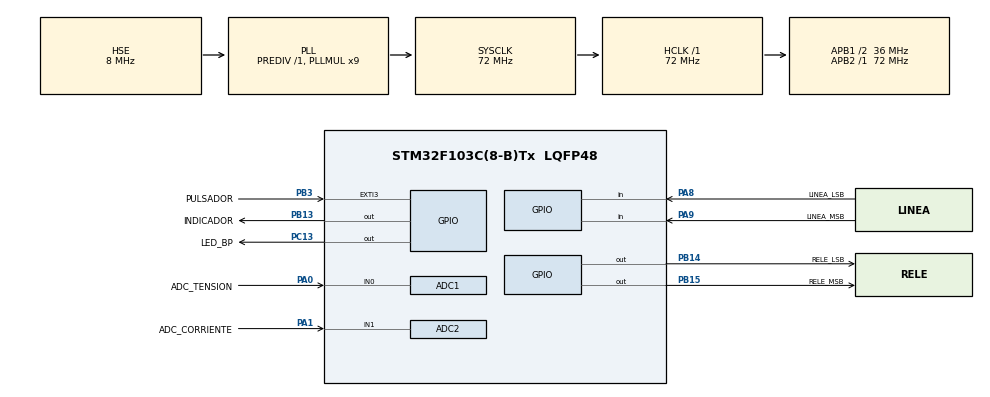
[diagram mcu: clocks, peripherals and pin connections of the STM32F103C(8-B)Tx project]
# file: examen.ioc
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ADC1.Channel-0\#ChannelRegularConversion=ADC_CHANNEL_0
ADC1.NbrOfConversionFlag=1
ADC1.Rank-0\#ChannelRegularConversion=1
ADC1.SamplingTime-0\#ChannelRegularConversion=ADC_SAMPLETIME_1CYCLE_5
ADC1.master=1
ADC2.Channel-0\#ChannelRegularConversion=ADC_CHANNEL_1
ADC2.NbrOfConversionFlag=1
ADC2.Rank-0\#ChannelRegularConversion=1
ADC2.SamplingTime-0\#ChannelRegularConversion=ADC_SAMPLETIME_1CYCLE_5
Dma.ADC1.0.Direction=DMA_PERIPH_TO_MEMORY
Dma.ADC1.0.Instance=DMA1_Channel1
Dma.ADC1.0.MemDataAlignment=DMA_MDATAALIGN_HALFWORD
Dma.ADC1.0.MemInc=DMA_MINC_ENABLE
Dma.ADC1.0.Mode=DMA_CIRCULAR
Dma.ADC1.0.PeriphDataAlignment=DMA_PDATAALIGN_HALFWORD
Dma.ADC1.0.PeriphInc=DMA_PINC_DISABLE
Dma.ADC1.0.Priority=DMA_PRIORITY_LOW
Dma.Request0=ADC1
Mcu.Family=STM32F1
Mcu.Name=STM32F103C(8-B)Tx
Mcu.Package=LQFP48
NVIC.DMA1_Channel1_IRQn=true\:0\:0\:false\:false\:true\:false\:true\:true
NVIC.PriorityGroup=NVIC_PRIORITYGROUP_4
PA0-WKUP.GPIO_Label=ADC_TENSION
PA0-WKUP.Signal=ADCx_IN0
PA1.GPIO_Label=ADC_CORRIENTE
PA1.Signal=ADCx_IN1
PA13.Mode=Serial_Wire
PA13.Signal=SYS_JTMS-SWDIO
PA14.Mode=Serial_Wire
PA14.Signal=SYS_JTCK-SWCLK
PA8.GPIO_Label=LINEA_LSB
PA8.Signal=GPIO_Input
PA9.GPIO_Label=LINEA_MSB
PA9.Signal=GPIO_Input
PB13.GPIO_Label=INDICADOR
PB13.Signal=GPIO_Output
PB14.GPIO_Label=RELE_LSB
PB14.Signal=GPIO_Output
PB15.GPIO_Label=RELE_MSB
PB15.Signal=GPIO_Output
PB3.GPIO_Label=PULSADOR
PB3.Signal=GPXTI3
PC13-TAMPER-RTC.GPIO_Label=LED_BP
PC13-TAMPER-RTC.Signal=GPIO_Output
PC14-OSC32_IN.Mode=LSE-External-Oscillator
PC14-OSC32_IN.Signal=RCC_OSC32_IN
PC15-OSC32_OUT.Mode=LSE-External-Oscillator
PC15-OSC32_OUT.Signal=RCC_OSC32_OUT
PD0-OSC_IN.Mode=HSE-External-Oscillator
PD0-OSC_IN.Signal=RCC_OSC_IN
PD1-OSC_OUT.Mode=HSE-External-Oscillator
PD1-OSC_OUT.Signal=RCC_OSC_OUT
ProjectManager.HeapSize=0x200
ProjectManager.StackSize=0x400
ProjectManager.TargetToolchain=STM32CubeIDE
RCC.AHBFreq_Value=72000000
RCC.APB1CLKDivider=RCC_HCLK_DIV2
RCC.APB1Freq_Value=36000000
RCC.APB1TimFreq_Value=72000000
RCC.APB2Freq_Value=72000000
RCC.APB2TimFreq_Value=72000000
RCC.HCLKFreq_Value=72000000
RCC.PLLMUL=RCC_PLL_MUL9
RCC.PLLSourceVirtual=RCC_PLLSOURCE_HSE
RCC.SYSCLKFreq_VALUE=72000000
RCC.SYSCLKSource=RCC_SYSCLKSOURCE_PLLCLK
RCC.USBFreq_Value=72000000
SH.ADCx_IN0.0=ADC1_IN0,IN0
SH.ADCx_IN1.0=ADC2_IN1,IN1
SH.ADCx_IN1.1=ADC1_IN1,IN1
board=custom

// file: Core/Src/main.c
/* USER CODE BEGIN Header */
/**
  ******************************************************************************
  * @file           : main.c
  * @brief          : Main program body
  ******************************************************************************
  * @attention
  *
  * <h2><center>&copy; Copyright (c) 2021 STMicroelectronics.
  * All rights reserved.</center></h2>
  *
  * This software component is licensed by ST under BSD 3-Clause license,
  * the "License"; You may not use this file except in compliance with the
  * License. You may obtain a copy of the License at:
  *                        opensource.org/licenses/BSD-3-Clause
  *
  ******************************************************************************
  */
/* USER CODE END Header */
#include "main.h"
#include "fsm.h"
#include "user_gpio.h"

ADC_HandleTypeDef hadc1;
ADC_HandleTypeDef hadc2;
DMA_HandleTypeDef hdma_adc1;

void SystemClock_Config(void);
static void MX_GPIO_Init(void);
static void MX_DMA_Init(void);
static void MX_ADC1_Init(void);
static void MX_ADC2_Init(void);

/* USER CODE BEGIN 0 */
void HAL_IncTick(void){
	uwTick += uwTickFreq;
	fsm_tick();
}
/* USER CODE END 0 */

int main(void)
{

  /* MCU Configuration--------------------------------------------------------*/

  /* Reset of all peripherals, Initializes the Flash interface and the Systick. */
  HAL_Init();

  /* Configure the system clock */
  SystemClock_Config();

  /* Initialize all configured peripherals */
  MX_GPIO_Init();
  MX_DMA_Init();
  MX_ADC1_Init();
  MX_ADC2_Init();
  /* USER CODE BEGIN 2 */
  fsm_init();
  user_gpio_init();
  /* USER CODE END 2 */

  /* Infinite loop */
  /* USER CODE BEGIN WHILE */
  while (1)
  {

	 fsm_runCycle();
	 user_gpio_loop();
    /* USER CODE END WHILE */

  }
}

void SystemClock_Config(void)
{
  RCC_OscInitTypeDef RCC_OscInitStruct = {0};
  RCC_ClkInitTypeDef RCC_ClkInitStruct = {0};
  RCC_PeriphCLKInitTypeDef PeriphClkInit = {0};

  /** Initializes the RCC Oscillators according to the specified parameters
  * in the RCC_OscInitTypeDef structure.
  */
  RCC_OscInitStruct.OscillatorType = RCC_OSCILLATORTYPE_HSE;
  RCC_OscInitStruct.HSEState = RCC_HSE_ON;
  RCC_OscInitStruct.HSEPredivValue = RCC_HSE_PREDIV_DIV1;
  RCC_OscInitStruct.HSIState = RCC_HSI_ON;
  RCC_OscInitStruct.PLL.PLLState = RCC_PLL_ON;
  RCC_OscInitStruct.PLL.PLLSource = RCC_PLLSOURCE_HSE;
  RCC_OscInitStruct.PLL.PLLMUL = RCC_PLL_MUL9;
  if (HAL_RCC_OscConfig(&RCC_OscInitStruct) != HAL_OK)
  {
    Error_Handler();
  }

  /** Initializes the CPU, AHB and APB buses clocks
  */
  RCC_ClkInitStruct.ClockType = RCC_CLOCKTYPE_HCLK|RCC_CLOCKTYPE_SYSCLK
                              |RCC_CLOCKTYPE_PCLK1|RCC_CLOCKTYPE_PCLK2;
  RCC_ClkInitStruct.SYSCLKSource = RCC_SYSCLKSOURCE_PLLCLK;
  RCC_ClkInitStruct.AHBCLKDivider = RCC_SYSCLK_DIV1;
  RCC_ClkInitStruct.APB1CLKDivider = RCC_HCLK_DIV2;
  RCC_ClkInitStruct.APB2CLKDivider = RCC_HCLK_DIV1;

  if (HAL_RCC_ClockConfig(&RCC_ClkInitStruct, FLASH_LATENCY_2) != HAL_OK)
  {
    Error_Handler();
  }
  PeriphClkInit.PeriphClockSelection = RCC_PERIPHCLK_ADC;
  PeriphClkInit.AdcClockSelection = RCC_ADCPCLK2_DIV2;
  if (HAL_RCCEx_PeriphCLKConfig(&PeriphClkInit) != HAL_OK)
  {
    Error_Handler();
  }
}

static void MX_ADC1_Init(void)
{

  ADC_ChannelConfTypeDef sConfig = {0};

  /** Common config
  */
  hadc1.Instance = ADC1;
  hadc1.Init.ScanConvMode = ADC_SCAN_DISABLE;
  hadc1.Init.ContinuousConvMode = DISABLE;
  hadc1.Init.DiscontinuousConvMode = DISABLE;
  hadc1.Init.ExternalTrigConv = ADC_SOFTWARE_START;
  hadc1.Init.DataAlign = ADC_DATAALIGN_RIGHT;
  hadc1.Init.NbrOfConversion = 1;
  if (HAL_ADC_Init(&hadc1) != HAL_OK)
  {
    Error_Handler();
  }

  /** Configure Regular Channel
  */
  sConfig.Channel = ADC_CHANNEL_0;
  sConfig.Rank = ADC_REGULAR_RANK_1;
  sConfig.SamplingTime = ADC_SAMPLETIME_1CYCLE_5;
  if (HAL_ADC_ConfigChannel(&hadc1, &sConfig) != HAL_OK)
  {
    Error_Handler();
  }

}

static void MX_ADC2_Init(void)
{

  ADC_ChannelConfTypeDef sConfig = {0};

  /** Common config
  */
  hadc2.Instance = ADC2;
  hadc2.Init.ScanConvMode = ADC_SCAN_DISABLE;
  hadc2.Init.ContinuousConvMode = DISABLE;
  hadc2.Init.DiscontinuousConvMode = DISABLE;
  hadc2.Init.ExternalTrigConv = ADC_SOFTWARE_START;
  hadc2.Init.DataAlign = ADC_DATAALIGN_RIGHT;
  hadc2.Init.NbrOfConversion = 1;
  if (HAL_ADC_Init(&hadc2) != HAL_OK)
  {
    Error_Handler();
  }

  /** Configure Regular Channel
  */
  sConfig.Channel = ADC_CHANNEL_1;
  sConfig.Rank = ADC_REGULAR_RANK_1;
  sConfig.SamplingTime = ADC_SAMPLETIME_1CYCLE_5;
  if (HAL_ADC_ConfigChannel(&hadc2, &sConfig) != HAL_OK)
  {
    Error_Handler();
  }

}

static void MX_DMA_Init(void)
{

  /* DMA controller clock enable */
  __HAL_RCC_DMA1_CLK_ENABLE();

  /* DMA interrupt init */
  /* DMA1_Channel1_IRQn interrupt configuration */
  HAL_NVIC_SetPriority(DMA1_Channel1_IRQn, 0, 0);
  HAL_NVIC_EnableIRQ(DMA1_Channel1_IRQn);

}

static void MX_GPIO_Init(void)
{
  GPIO_InitTypeDef GPIO_InitStruct = {0};

  /* GPIO Ports Clock Enable */
  __HAL_RCC_GPIOC_CLK_ENABLE();
  __HAL_RCC_GPIOD_CLK_ENABLE();
  __HAL_RCC_GPIOA_CLK_ENABLE();
  __HAL_RCC_GPIOB_CLK_ENABLE();

  /*Configure GPIO pin Output Level */
  HAL_GPIO_WritePin(LED_BP_GPIO_Port, LED_BP_Pin, GPIO_PIN_RESET);

  /*Configure GPIO pin Output Level */
  HAL_GPIO_WritePin(GPIOB, INDICADOR_Pin|RELE_LSB_Pin|RELE_MSB_Pin, GPIO_PIN_RESET);

  /*Configure GPIO pin : LED_BP_Pin */
  GPIO_InitStruct.Pin = LED_BP_Pin;
  GPIO_InitStruct.Mode = GPIO_MODE_OUTPUT_PP;
  GPIO_InitStruct.Pull = GPIO_NOPULL;
  GPIO_InitStruct.Speed = GPIO_SPEED_FREQ_LOW;
  HAL_GPIO_Init(LED_BP_GPIO_Port, &GPIO_InitStruct);

  /*Configure GPIO pins : INDICADOR_Pin RELE_LSB_Pin RELE_MSB_Pin */
  GPIO_InitStruct.Pin = INDICADOR_Pin|RELE_LSB_Pin|RELE_MSB_Pin;
  GPIO_InitStruct.Mode = GPIO_MODE_OUTPUT_PP;
  GPIO_InitStruct.Pull = GPIO_NOPULL;
  GPIO_InitStruct.Speed = GPIO_SPEED_FREQ_LOW;
  HAL_GPIO_Init(GPIOB, &GPIO_InitStruct);

  /*Configure GPIO pins : LINEA_LSB_Pin LINEA_MSB_Pin */
  GPIO_InitStruct.Pin = LINEA_LSB_Pin|LINEA_MSB_Pin;
  GPIO_InitStruct.Mode = GPIO_MODE_INPUT;
  GPIO_InitStruct.Pull = GPIO_NOPULL;
  HAL_GPIO_Init(GPIOA, &GPIO_InitStruct);

  /*Configure GPIO pin : PULSADOR_Pin */
  GPIO_InitStruct.Pin = PULSADOR_Pin;
  GPIO_InitStruct.Mode = GPIO_MODE_IT_RISING;
  GPIO_InitStruct.Pull = GPIO_NOPULL;
  HAL_GPIO_Init(PULSADOR_GPIO_Port, &GPIO_InitStruct);

}

void Error_Handler(void)
{
  __disable_irq();
  while (1)
  {
  }
}
